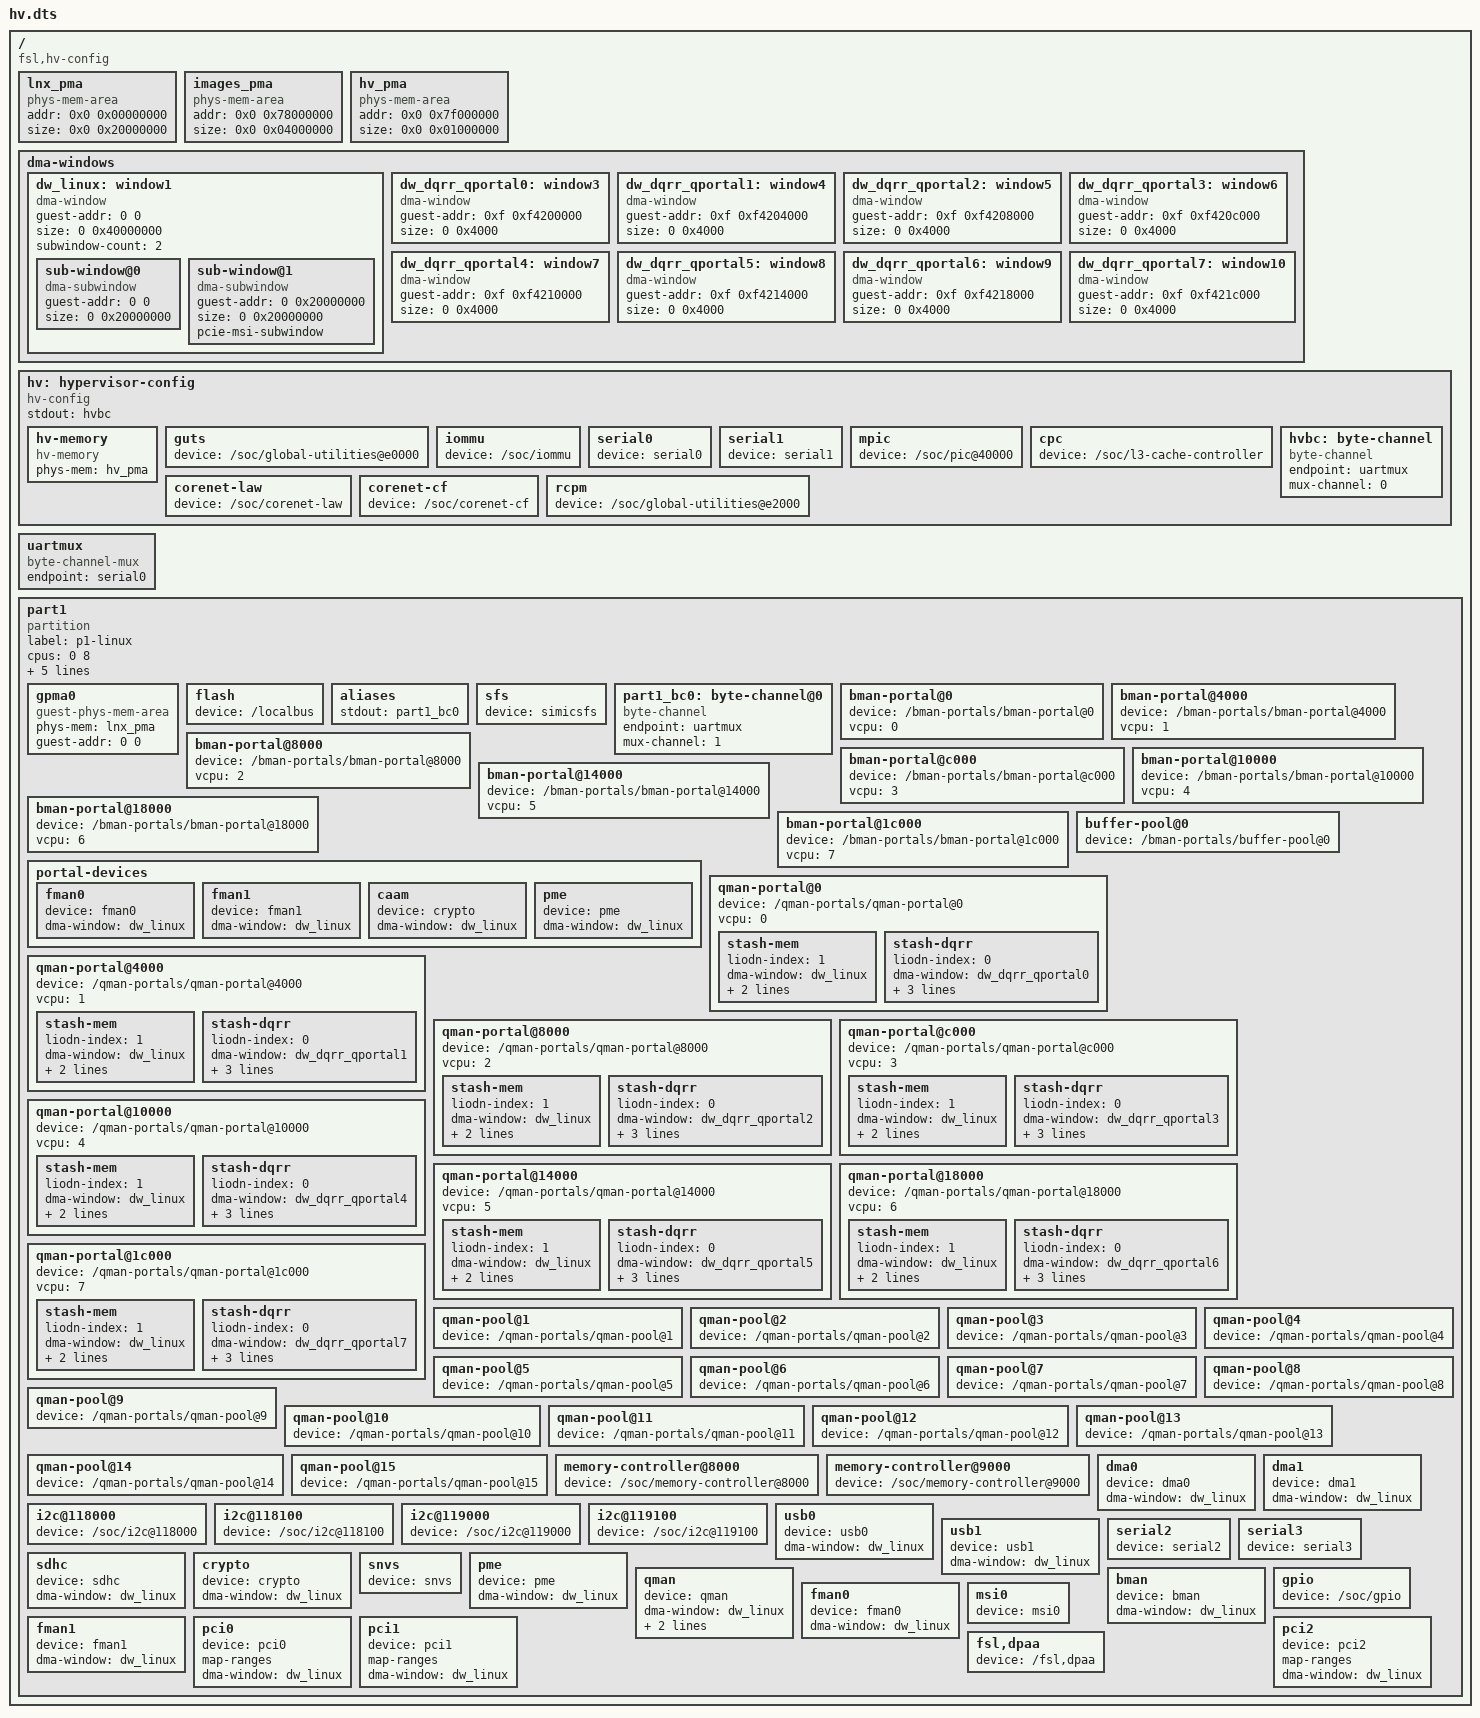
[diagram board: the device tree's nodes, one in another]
/* Hypervisor Configuration tree containing all hypervisor configuration
 * parameters and partition definition information.
 * (Note -- Please refer to Hypervisor SW Reference Manual
 * (Chapter 5 Configuration) for further details)
 *
 * Copyright (c) 2009-2010 Freescale Semiconductor, Inc.
 */

/dts-v1/;

/ {     // root node

        // The root node of the configuration device tree must contain a
        // compatible property that identifies the device tree as a hypervisor
	compatible = "fsl,hv-config";

	// =====================================================
	// Physical Memory Areas
	// =====================================================
	lnx_pma: lnx_pma {
		compatible = "phys-mem-area";
		addr = <0x0 0x00000000>;	// Linux
		size = <0x0 0x20000000>;	// 512MB
	};
	images_pma: images_pma {
		compatible = "phys-mem-area";
		addr = <0x0 0x78000000>;	// Used for boot-from-RAM
 		size = <0x0 0x04000000>;	// 64MB
 	};
	hv_pma: hv_pma {
		compatible = "phys-mem-area";
		addr = <0x0 0x7f000000>;	// Hypervisor
		size = <0x0 0x01000000>;	// 16MB
	};

	// =====================================================
        // DMA Windows
        // =====================================================
	dma-windows {
		dw_linux: window1 {		// DMA window for linux
			compatible = "dma-window";
			guest-addr = <0 0>;
			size = <0 0x40000000>; //1GB
			subwindow-count = <2>;
			sub-window@0 {
				compatible = "dma-subwindow";
				guest-addr = <0 0>;
				size = <0 0x20000000>; // 512MB
			};
			sub-window@1 {		// MSI sub-window
				compatible = "dma-subwindow";
				guest-addr = <0 0x20000000>;
				size = <0 0x20000000>; // 512MB
				pcie-msi-subwindow;
			};
		};
		dw_dqrr_qportal0: window3 {	// DMA window for stash_dqrr for qman-portal0
			compatible = "dma-window";
			guest-addr = <0xf 0xf4200000>;
			size = <0 0x4000>;
		};
		dw_dqrr_qportal1: window4 {	// DMA window for stash_dqrr for qman-portal1
			compatible = "dma-window";
			guest-addr = <0xf 0xf4204000>;
			size = <0 0x4000>;
		};
		dw_dqrr_qportal2: window5 {	// DMA window for stash_dqrr for qman-portal2
			compatible = "dma-window";
			guest-addr = <0xf 0xf4208000>;
			size = <0 0x4000>;
		};
		dw_dqrr_qportal3: window6 {	// DMA window for stash_dqrr for qman-portal3
			compatible = "dma-window";
			guest-addr = <0xf 0xf420c000>;
			size = <0 0x4000>;
		};
		dw_dqrr_qportal4: window7 {	// DMA window for stash_dqrr for qman-portal4
			compatible = "dma-window";
			guest-addr = <0xf 0xf4210000>;
			size = <0 0x4000>;
		};
		dw_dqrr_qportal5: window8 {	// DMA window for stash_dqrr for qman-portal5
			compatible = "dma-window";
			guest-addr = <0xf 0xf4214000>;
			size = <0 0x4000>;
		};
		dw_dqrr_qportal6: window9 {	// DMA window for stash_dqrr for qman-portal6
			compatible = "dma-window";
			guest-addr = <0xf 0xf4218000>;
			size = <0 0x4000>;
		};
		dw_dqrr_qportal7: window10 {	// DMA window for stash_dqrr for qman-portal7
			compatible = "dma-window";
			guest-addr = <0xf 0xf421c000>;
			size = <0 0x4000>;
		};
	};

	// =====================================================
	// Hypervisor Config
        // Hypervisor is also configured via the Hypervisor
        // configuration tree. A special node and subtree defines
        // set of global configuration parameters and a number of
        // device nodes assigning I/O devices to the hypervisor
	// =====================================================
	hv: hypervisor-config {
		compatible = "hv-config";
		// phandle to byte-channel used for hypervisor's console
		stdout = <&hvbc>;

		// Hypervisor private memory
		hv-memory {
			compatible = "hv-memory";
			phys-mem = <&hv_pma>;
		};

		// Device nodes given below are the physical I/O
                // devices assigned to hypervisor.

                // Global Utilities node

                guts {
                        device = "/soc/global-utilities@e0000";
                };

		iommu {
			device = "/soc/iommu";
		};

		serial0: serial0 {
			device = "serial0";
		};
		serial1: serial1 {
			device = "serial1";
		};

		mpic {
			device = "/soc/pic@40000";
		};

		cpc {
			device = "/soc/l3-cache-controller";
		};

		corenet-law {
			device = "/soc/corenet-law";
		};

		corenet-cf {
			device = "/soc/corenet-cf";
		};

		rcpm {
			device = "/soc/global-utilities@e2000";
		};

		// Byte channel used as hypervisor's console
		hvbc: byte-channel {
			compatible = "byte-channel";
			endpoint = <&uartmux>;
			mux-channel = <0>;
		};
	};

	// =====================================================
        // UART mux
        // This node is referenced by byte-channels that use mux
        // as an endpoint
        // =====================================================
	uartmux: uartmux {
		compatible = "byte-channel-mux";
		endpoint = <&serial0>;
	};

	 // =====================================================
        // To keep the scenarios hv-1/2/4p as diff-able as possible
        // we always use labels part1 and part2 for linux partitions and
        // part3 and part4 for LWE partitions.
        // In hv-1p scenario, there is 1 partition - 1 Linux
        // Partition1 --- part1 --- Linux partition
        // =====================================================

	// =====================================================
	// Partition 1 -- Linux Partition
	// =====================================================
	part1 {
		 // Indicates that it is a partition node
		compatible = "partition";
	
		 // Optional property which provides a readable label to the partition
		label = "p1-linux";

		// All CPUs 0 to 8 assigned to this partition
		cpus = <0 8>;

		// Addr and size  of the guest image to be
                //loaded by hypervisor prior to the partition start.
		guest-image = <0xf 0xe8020000 0 0 0 0x700000>;

		 // Addr and size of the linux-rootfs to be loaded by
                // hypervisor prior to partition start
		linux-rootfs = <0xf 0xe9300000 0 0x01300000 0 0x02800000>;

		dtb-window = <0 0x01000000 0 0x00012000>;

		// Temporary until Linux uses enable LIODN hcall
		no-dma-disable;

		gpma0 {
			compatible = "guest-phys-mem-area";
			phys-mem = <&lnx_pma>;
			guest-addr = <0 0>;
		};

		flash {
			device = "/localbus";
		};

		aliases {
			stdout = <&part1_bc0>;
		};

		sfs {
			device = "simicsfs";
		};

		// Byte channel used for stdout interface attached to mux-channel 1
		part1_bc0: byte-channel@0 {
			compatible = "byte-channel";
			endpoint = <&uartmux>;
			mux-channel = <1>;
		};

		bman-portal@0 {
			device = "/bman-portals/bman-portal@0";

			vcpu = <0>;
		};
		bman-portal@4000 {
			device = "/bman-portals/bman-portal@4000";

			vcpu = <1>;
		};
		bman-portal@8000 {
			device = "/bman-portals/bman-portal@8000";

			vcpu = <2>;
		};
		bman-portal@c000 {
			device = "/bman-portals/bman-portal@c000";

			vcpu = <3>;
		};
		bman-portal@10000 {
			device = "/bman-portals/bman-portal@10000";

			vcpu = <4>;
		};
		bman-portal@14000 {
			device = "/bman-portals/bman-portal@14000";

			vcpu = <5>;
		};
		bman-portal@18000 {
			device = "/bman-portals/bman-portal@18000";

			vcpu = <6>;
		};
		bman-portal@1c000 {
			device = "/bman-portals/bman-portal@1c000";

			vcpu = <7>;
		};

		buffer-pool@0 {
			device = "/bman-portals/buffer-pool@0";
		};

		portal-devices {
			fman0 {
				device = "fman0";
				dma-window = <&dw_linux>;
			};
			fman1 {
				device = "fman1";
				dma-window = <&dw_linux>;
			};
			caam {
				device = "crypto";
				dma-window = <&dw_linux>;
			};
			pme {
				device = "pme";
				dma-window = <&dw_linux>;
			};
		};

		qman-portal@0 {
			device = "/qman-portals/qman-portal@0";
			vcpu = <0>;

			stash-mem {
				liodn-index = <1>;
				dma-window = <&dw_linux>;
				operation-mapping = <0>;	// OMI_QMAN
				stash-dest = <1>;
			};

			stash-dqrr {
				liodn-index = <0>;
				dma-window = <&dw_dqrr_qportal0>;
				operation-mapping = <0>;	// OMI_QMAN
				stash-dest = <1>;
				snoop-cpu-only;
			};
		};

		qman-portal@4000 {
			device = "/qman-portals/qman-portal@4000";
			vcpu = <1>;

			stash-mem {
				liodn-index = <1>;
				dma-window = <&dw_linux>;
				operation-mapping = <0>;	// OMI_QMAN
				stash-dest = <1>;
			};

			stash-dqrr {
				liodn-index = <0>;
				dma-window = <&dw_dqrr_qportal1>;
				operation-mapping = <0>;	// OMI_QMAN
				stash-dest = <1>;
				snoop-cpu-only;
			};
		};

		qman-portal@8000 {
			device = "/qman-portals/qman-portal@8000";
			vcpu = <2>;

			stash-mem {
				liodn-index = <1>;
				dma-window = <&dw_linux>;
				operation-mapping = <0>;	// OMI_QMAN
				stash-dest = <1>;
			};

			stash-dqrr {
				liodn-index = <0>;
				dma-window = <&dw_dqrr_qportal2>;
				operation-mapping = <0>;	// OMI_QMAN
				stash-dest = <1>;
				snoop-cpu-only;
			};
		};

		qman-portal@c000 {
			device = "/qman-portals/qman-portal@c000";
			vcpu = <3>;

			stash-mem {
				liodn-index = <1>;
				dma-window = <&dw_linux>;
				operation-mapping = <0>;	// OMI_QMAN
				stash-dest = <1>;
			};

			stash-dqrr {
				liodn-index = <0>;
				dma-window = <&dw_dqrr_qportal3>;
				operation-mapping = <0>;	// OMI_QMAN
				stash-dest = <1>;
				snoop-cpu-only;
			};
		};

		qman-portal@10000 {
			device = "/qman-portals/qman-portal@10000";
			vcpu = <4>;

			stash-mem {
				liodn-index = <1>;
				dma-window = <&dw_linux>;
				operation-mapping = <0>;	// OMI_QMAN
				stash-dest = <1>;
			};

			stash-dqrr {
				liodn-index = <0>;
				dma-window = <&dw_dqrr_qportal4>;
				operation-mapping = <0>;	// OMI_QMAN
				stash-dest = <1>;
				snoop-cpu-only;
			};
		};

		qman-portal@14000 {
			device = "/qman-portals/qman-portal@14000";
			vcpu = <5>;

			stash-mem {
				liodn-index = <1>;
				dma-window = <&dw_linux>;
				operation-mapping = <0>;	// OMI_QMAN
				stash-dest = <1>;
			};

			stash-dqrr {
				liodn-index = <0>;
				dma-window = <&dw_dqrr_qportal5>;
				operation-mapping = <0>;	// OMI_QMAN
				stash-dest = <1>;
				snoop-cpu-only;
			};
		};

		qman-portal@18000 {
			device = "/qman-portals/qman-portal@18000";
			vcpu = <6>;

			stash-mem {
				liodn-index = <1>;
				dma-window = <&dw_linux>;
				operation-mapping = <0>;	// OMI_QMAN
				stash-dest = <1>;
			};

			stash-dqrr {
				liodn-index = <0>;
				dma-window = <&dw_dqrr_qportal6>;
				operation-mapping = <0>;	// OMI_QMAN
				stash-dest = <1>;
				snoop-cpu-only;
			};
		};

		qman-portal@1c000 {
			device = "/qman-portals/qman-portal@1c000";
			vcpu = <7>;

			stash-mem {
				liodn-index = <1>;
				dma-window = <&dw_linux>;
				operation-mapping = <0>;	// OMI_QMAN
				stash-dest = <1>;
			};

			stash-dqrr {
				liodn-index = <0>;
				dma-window = <&dw_dqrr_qportal7>;
				operation-mapping = <0>;	// OMI_QMAN
				stash-dest = <1>;
				snoop-cpu-only;
			};
		};

		qman-pool@1 {
			device = "/qman-portals/qman-pool@1";
		};
		qman-pool@2 {
			device = "/qman-portals/qman-pool@2";
		};
		qman-pool@3 {
			device = "/qman-portals/qman-pool@3";
		};
		qman-pool@4 {
			device = "/qman-portals/qman-pool@4";
		};
		qman-pool@5 {
			device = "/qman-portals/qman-pool@5";
		};
		qman-pool@6 {
			device = "/qman-portals/qman-pool@6";
		};
		qman-pool@7 {
			device = "/qman-portals/qman-pool@7";
		};
		qman-pool@8 {
			device = "/qman-portals/qman-pool@8";
		};
		qman-pool@9 {
			device = "/qman-portals/qman-pool@9";
		};
		qman-pool@10 {
			device = "/qman-portals/qman-pool@10";
		};
		qman-pool@11 {
			device = "/qman-portals/qman-pool@11";
		};
		qman-pool@12 {
			device = "/qman-portals/qman-pool@12";
		};
		qman-pool@13 {
			device = "/qman-portals/qman-pool@13";
		};
		qman-pool@14 {
			device = "/qman-portals/qman-pool@14";
		};
		qman-pool@15 {
			device = "/qman-portals/qman-pool@15";
		};

		memory-controller@8000 {
			device = "/soc/memory-controller@8000";
		};
		memory-controller@9000 {
			device = "/soc/memory-controller@9000";
		};

		dma0 {
			device = "dma0";
			dma-window = <&dw_linux>;
		};
		dma1 {
			device = "dma1";
			dma-window = <&dw_linux>;
		};

		i2c@118000 {
			device = "/soc/i2c@118000";
		};
		i2c@118100 {
			device = "/soc/i2c@118100";
		};
		i2c@119000 {
			device = "/soc/i2c@119000";
		};
		i2c@119100 {
			device = "/soc/i2c@119100";
		};

		usb0 {
			device = "usb0";
			dma-window = <&dw_linux>;
		};
		usb1 {
			device = "usb1";
			dma-window = <&dw_linux>;
		};

		serial2 {
			device = "serial2";
		};
		serial3 {
			device = "serial3";
		};

		sdhc {
			device = "sdhc";
			dma-window = <&dw_linux>;
		};

		crypto {
			device = "crypto";
			dma-window = <&dw_linux>;
		};

		snvs {
			device = "snvs";
		};

		pme {
			device = "pme";
			dma-window = <&dw_linux>;
		};

		qman {
			device = "qman";
			dma-window = <&dw_linux>;
			operation-mapping = <2>;	// OMI_QMAN_PRIV
			stash-dest = <3>;		// L3/CPC
		};

		bman {
			device = "bman";
			dma-window = <&dw_linux>;
		};

		gpio {
			device = "/soc/gpio";
		};

		fman0 {
			device = "fman0";
			dma-window = <&dw_linux>;
		};
		fman1 {
			device = "fman1";
			dma-window = <&dw_linux>;
		};

		msi0 {
			device = "msi0";
		};
		pci0 {
			device = "pci0";
			map-ranges;
			dma-window = <&dw_linux>;
		};
		pci1 {
			device = "pci1";
			map-ranges;
			dma-window = <&dw_linux>;
		};
		pci2 {
			device = "pci2";
			map-ranges;
			dma-window = <&dw_linux>;
		};

		fsl,dpaa {
			device = "/fsl,dpaa";
		};
	};
};
